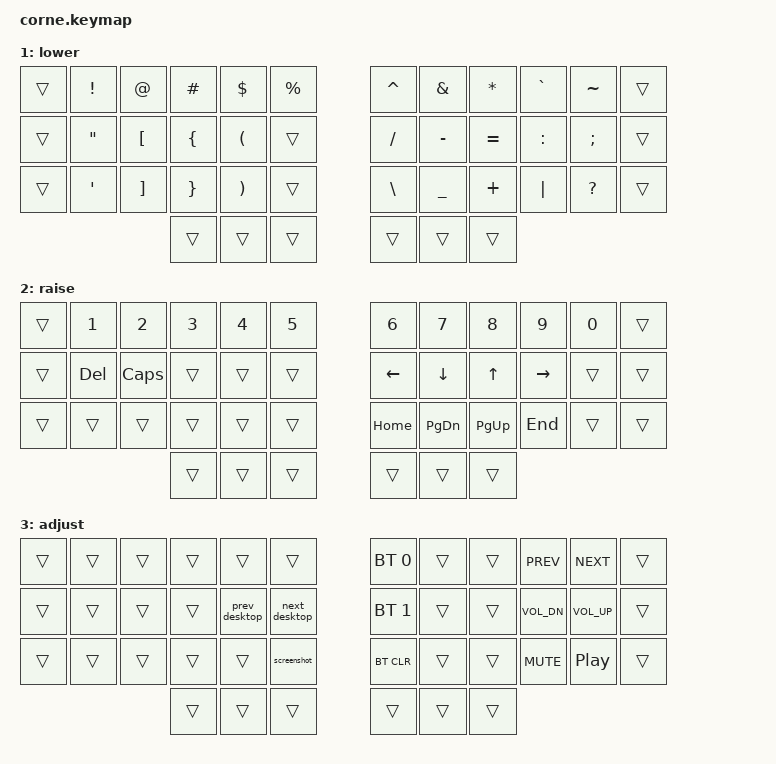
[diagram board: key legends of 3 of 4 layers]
/*
 * Copyright (c) 2020 The ZMK Contributors
 *
 * SPDX-License-Identifier: MIT
 */

#include <behaviors.dtsi>
#include <dt-bindings/zmk/bt.h>
#include <dt-bindings/zmk/keys.h>

// dt-formatter: indent = "  "
// dt-formatter: reindentMultilineIntegerCells = "dedent"

// home row mods macros
#define LHRM(k1, k2, k3, k4) &lhmr LCTRL k1  &lhmr LALT k2  &lhmr LGUI k3  &lhmr LSHIFT k4
#define RHRM(k1, k2, k3, k4) &rhmr RSHIFT k1  &rhmr RGUI k2  &rhmr RALT k3  &rhmr RCTRL k4

#define LOWER  1
#define RAISE  2
#define ADJUST 3

/ {
  combos {
    compatible = "zmk,combos";

    caps_word {
      bindings = <&caps_word>;
      // G - H
      key-positions = <17 18>;
    };

    esc {
      bindings = <&kp ESC>;
      // J - K
      key-positions = <19 20>;
    };
  };

  macros {
    screenshot: screenshot {
      compatible = "zmk,behavior-macro";
      #binding-cells = <0>;
      bindings =
        <&macro_press>,
        <&kp LGUI &kp LSHIFT>,
        <&macro_tap>,
        <&kp N4>,
        <&macro_release>,
        <&kp LGUI &kp LSHIFT>;
    };

    next_desktop: next_desktop {
      compatible = "zmk,behavior-macro";
      #binding-cells = <0>;
      bindings =
        <&macro_press>,
        <&kp LCTRL>,
        <&macro_tap>,
        <&kp RIGHT>,
        <&macro_release>,
        <&kp LCTRL>;
    };

    prev_desktop: prev_desktop {
      compatible = "zmk,behavior-macro";
      #binding-cells = <0>;
      bindings =
        <&macro_press>,
        <&kp LCTRL>,
        <&macro_tap>,
        <&kp LEFT>,
        <&macro_release>,
        <&kp LCTRL>;
    };
  };

  behaviors {
    rhmr: rhmr {
      compatible = "zmk,behavior-hold-tap";
      bindings = <&kp>, <&kp>;

      #binding-cells = <2>;
      tapping-term-ms = <300>;
      quick-tap-ms = <250>;
      flavor = "tap-preferred";
      require-prior-idle-ms = <150>;
      hold-trigger-key-positions = <0 1 2 3 4 5 12 13 14 15 16 17 24 25 26 27 28 29 36 37 38 39 40 41>;
    };

    lhmr: lhmr {
      compatible = "zmk,behavior-hold-tap";
      bindings = <&kp>, <&kp>;

      #binding-cells = <2>;
      tapping-term-ms = <300>;
      quick-tap-ms = <250>;
      flavor = "tap-preferred";
      require-prior-idle-ms = <150>;
      hold-trigger-key-positions = <6 7 8 9 10 11 18 19 20 21 22 23 30 31 32 33 34 35 36 37 38 39 40 41>;
    };
  };

  conditional_layers {
    compatible = "zmk,conditional-layers";

    adjust_layer {
      if-layers = <LOWER RAISE>;
      then-layer = <ADJUST>;
    };
  };

  keymap {
    compatible = "zmk,keymap";

    base {
      bindings = <
    //╭──────────┬──────────┬──────────┬──────────┬───────────┬──────────╮    ╭──────────┬───────────┬──────────┬──────────┬──────────┬──────────╮
    //│  TAB     │  Q       │  W       │  E       │  R        │  T       │    │  Y       │  U        │  I       │  O       │  P       │BACKSPACE │
        &kp TAB    &kp Q       &kp W     &kp E      &kp R       &kp T           &kp Y      &kp U       &kp I      &kp O      &kp P      &kp BSPC
    //├──────────┼──────────┼──────────┼──────────┼───────────┼──────────┤    ├──────────┼───────────┼──────────┼──────────┼──────────┼──────────┤
    //│  CTRL    │  A       │  S       │  D       │  F        │  G       │    │  H       │  J        │  K       │  L       │  ;       │  "       │
        &kp LCTRL  LHRM(A,     S,         D,         F)        &kp G           &kp H       RHRM(J,      K,         L,         SEMI)     &kp APOS
    //├──────────┼──────────┼──────────┼──────────┼───────────┼──────────┤    ├──────────┼───────────┼──────────┼──────────┼──────────┼──────────┤
    //│  SHIFT   │  Z       │  X       │  C       │  V        │  B       │    │  N       │  M        │  ,       │  .       │  /       │  SHIFT   │
        &kp LSHFT  &kp Z      &kp X      &kp C      &kp V      &kp B            &kp N      &kp M       &kp COMMA  &kp DOT    &kp FSLH  &kp RSHIFT
    //╰──────────┴──────────┴──────────┼──────────┼───────────┼──────────┤    ┤──────────┼───────────┼──────────┼──────────┴──────────┴──────────╯
    //                                 │  CMD     │  RAISE    │  SPACE   │    │  ENTER   │  LOWER    │  ALT     │
                                          &kp LGUI   &mo RAISE  &kp SPACE        &kp RET    &mo LOWER   &kp RALT
    //                                 ╰──────────┴───────────┴──────────╯    ╰──────────┴───────────┴──────────╯
      >;
    };

    lower {
      bindings = <
    //╭──────────┬──────────┬──────────┬──────────┬──────────┬──────────╮    ╭──────────┬──────────┬──────────┬──────────┬──────────┬──────────╮
    //│          │  !       │  @       │  #       │  $       │  %       │    │  ^       │  &       │  *       │  `       │  ~       │          │
        &trans     &kp EXCL   &kp AT     &kp HASH   &kp DLLR   &kp PRCNT       &kp CARET  &kp AMPS   &kp ASTRK  &kp GRAVE  &kp TILDE  &trans
    //├──────────┼──────────┼──────────┼──────────┼──────────┼──────────┤    ├──────────┼──────────┼──────────┼──────────┼──────────┼──────────┤
    //│          │  "       │  [       │  {       │  (       │          │    │  /       │  -       │  =       │  :       │  ;       │          │
        &trans     &kp DQT    &kp LBKT   &kp LBRC   &kp LPAR   &trans          &kp FSLH   &kp MINUS  &kp EQUAL  &kp COLON  &kp SEMI   &trans
    //├──────────┼──────────┼──────────┼──────────┼──────────┼──────────┤    ├──────────┼──────────┼──────────┼──────────┼──────────┼──────────┤
    //│          │  '       │  ]       │  }       │  )       │          │    │  \       │  _       │  +       │  |       │  ?       │          │
        &trans     &kp SQT    &kp RBKT   &kp RBRC   &kp RPAR   &trans          &kp BSLH  &kp UNDER   &kp PLUS   &kp PIPE   &kp QMARK  &trans
    //╰──────────┴──────────┴──────────┼──────────┼──────────┼──────────┤    ┤──────────┼──────────┼──────────┼──────────┴──────────┴──────────╯
                                         &trans     &trans     &trans          &trans     &trans     &trans
    //                                 ╰──────────┴──────────┴──────────╯    ╰──────────┴──────────┴──────────╯
      >;
    };

    raise {
      bindings = <
    //╭──────────┬──────────┬──────────┬──────────┬──────────┬──────────╮    ╭──────────┬──────────┬────────────┬──────────┬──────────┬──────────╮
    //│          │  1       │  2       │  3       │  4       │  5       │    │  6       │  7       │  8         │  9       │  0       │          │
        &trans     &kp N1     &kp N2     &kp N3     &kp N4     &kp N5          &kp N6     &kp N7     &kp N8       &kp N9     &kp N0      &trans
    //├──────────┼──────────┼──────────┼──────────┼──────────┼──────────┤    ├──────────┼──────────┼────────────┼──────────┼──────────┼──────────┤
    //│          │  DEL     │ CAPS     │          │          │          │    │  LEFT    │  DOWN    │  UP        │  RIGHT   │          │          │
        &trans     &kp DEL    &kp CAPS   &trans     &trans     &trans          &kp LEFT   &kp DOWN   &kp UP       &kp RIGHT  &trans     &trans
    //├──────────┼──────────┼──────────┼──────────┼──────────┼──────────┤    ├──────────┼──────────┼────────────┼──────────┼──────────┼──────────┤
    //│          │          │          │          │          │          │    │  HOME    │  PG DOWN │  PG UP     │  END     │          │          │
        &trans     &trans     &trans     &trans     &trans     &trans          &kp HOME   &kp PG_DN   &kp PG_UP   &kp END    &trans     &trans
    //╰──────────┴──────────┴──────────┼──────────┼──────────┼──────────┤    ┤──────────┼──────────┼────────────┼──────────┴──────────┴──────────╯
                                         &trans     &trans     &trans          &trans     &trans     &trans
    //                                 ╰──────────┴──────────┴──────────╯    ╰──────────┴──────────┴────────────╯
      >;
    };

    adjust {
      bindings = <
    //╭──────────┬──────────┬──────────┬──────────┬───────────────┬──────────────╮    ╭─────────────┬──────────┬──────────┬─────────────┬─────────────┬──────────╮
    //│          │          │          │          │               │              │    │ PROFILE 1   │          │          │ PREVSONG    │ NEXTSONG    │          │
        &trans     &trans     &trans     &trans     &trans          &trans              &bt BT_SEL 0  &trans     &trans     &kp C_PREV    &kp C_NEXT    &trans
    //├──────────┼──────────┼──────────┼──────────┼───────────────┼──────────────┤    ├─────────────┼──────────┼──────────┼─────────────┼─────────────┼──────────┤
    //│          │          │          │          │ PREV DESKTOP  │ NEXT DESKTOP │    │ PROFILE 2   │          │          │ VOL DOWN    │  VOL UP     │          │
        &trans     &trans     &trans     &trans     &prev_desktop   &next_desktop       &bt BT_SEL 1  &trans     &trans     &kp C_VOL_DN  &kp C_VOL_UP  &trans
    //├──────────┼──────────┼──────────┼──────────┼───────────────┼──────────────┤    ├─────────────┼──────────┼──────────┼─────────────┼─────────────┼──────────┤
    //│          │          │          │          │               │ SCREENSHOT   │    │ CLEAR BT    │          │          │ MUTE        │ PLAY_PAUSE  │          │
        &trans     &trans     &trans     &trans     &trans          &screenshot         &bt BT_CLR    &trans     &trans     &kp C_MUTE    &kp C_PP      &trans
    //╰──────────┴──────────┴──────────┼──────────┼───────────────┼──────────────┤    ┤─────────────┼──────────┼──────────┼─────────────┴─────────────┴──────────╯
                                         &trans     &trans          &trans              &trans        &trans     &trans
    //                                 ╰──────────┴───────────────┴──────────────╯    ╰─────────────┴──────────┴──────────╯
      >;
    };
  }; 
};

/* vim: set ft=c tw=174: */
